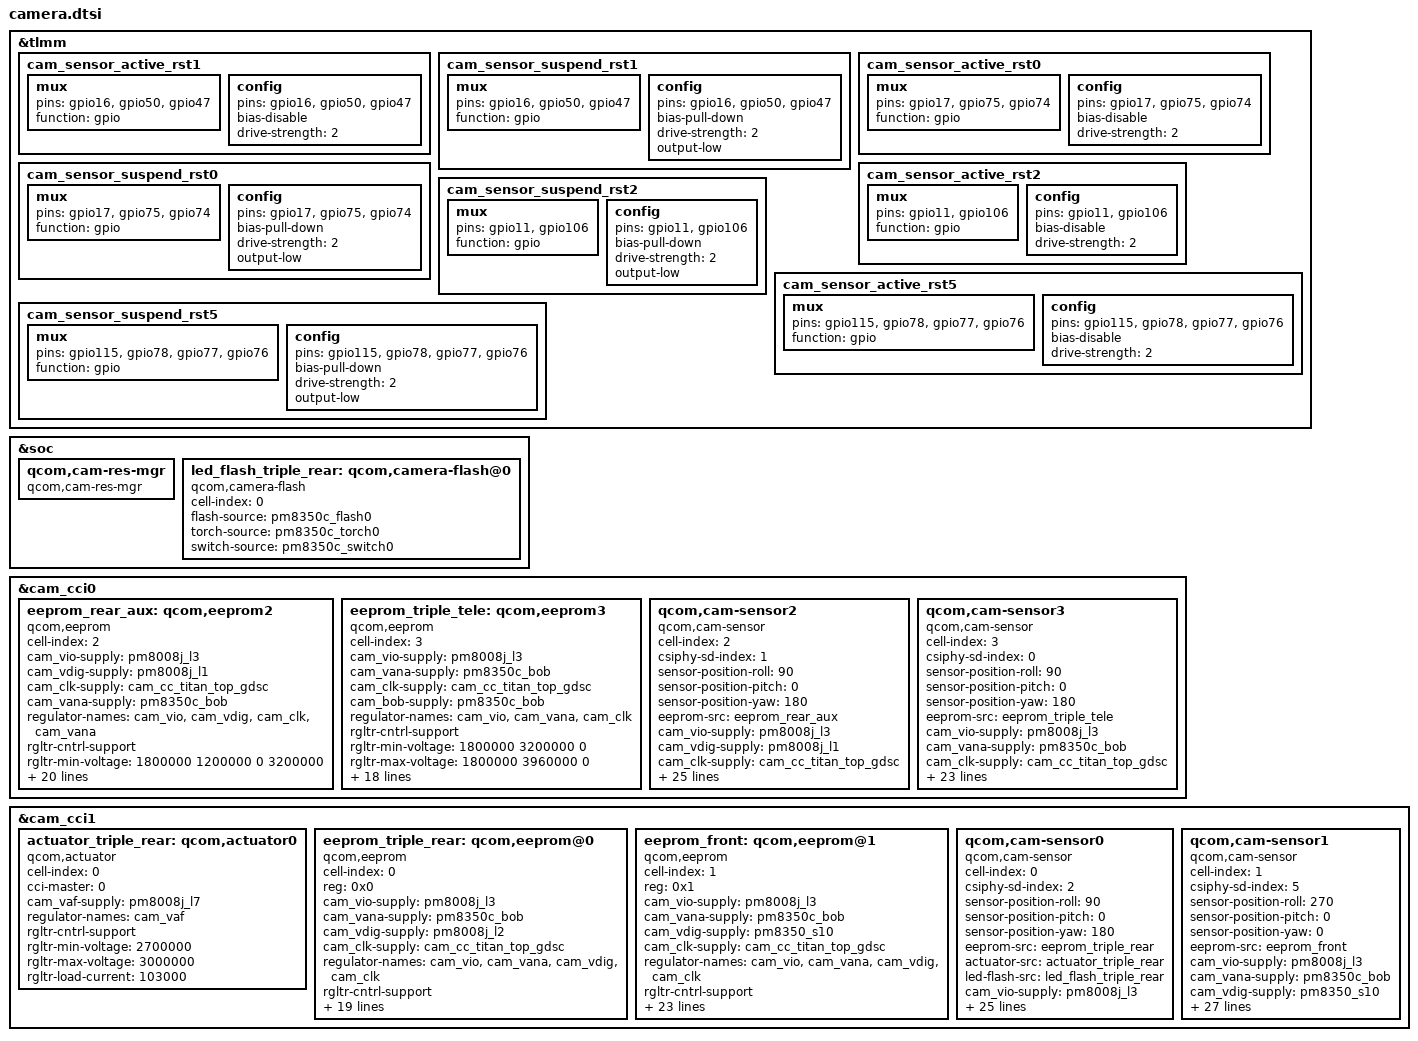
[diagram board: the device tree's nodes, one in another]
#include <dt-bindings/clock/qcom,camcc-lahaina.h>

&tlmm {
	/delete-node/ cam_sensor_active_rst0;
	/delete-node/ cam_sensor_suspend_rst0;
	/delete-node/ cam_sensor_active_rst5;
	/delete-node/ cam_sensor_suspend_rst5;
	/delete-node/ cam_sensor_active_rst1;
	/delete-node/ cam_sensor_suspend_rst1;
	/delete-node/ cam_sensor_active_rst2;
	/delete-node/ cam_sensor_suspend_rst2;
	
	cam_sensor_active_rst1: cam_sensor_active_rst1 {
			/* RESET 1 */
			mux {
				pins = "gpio16","gpio50","gpio47";
				function = "gpio";
			};

			config {
				pins = "gpio16","gpio50","gpio47";
				bias-disable; /* No PULL */
				drive-strength = <2>; /* 2 MA */
			};
		};

		cam_sensor_suspend_rst1: cam_sensor_suspend_rst1 {
			/* RESET 1 */
			mux {
				pins = "gpio16","gpio50","gpio47";
				function = "gpio";
			};

			config {
				pins = "gpio16","gpio50","gpio47";
				bias-pull-down; /* PULL DOWN */
				drive-strength = <2>; /* 2 MA */
				output-low;
			};
		};
	cam_sensor_active_rst0: cam_sensor_active_rst0 {
            /* RESET REAR */
            mux {
                    pins = "gpio17","gpio75","gpio74";
                    function = "gpio";
            };

            config {
                    pins = "gpio17","gpio75","gpio74";
                    bias-disable; /* No PULL */
                    drive-strength = <2>; /* 2 MA */
            };
    };

    cam_sensor_suspend_rst0: cam_sensor_suspend_rst0 {
            /* RESET REAR */
            mux {
                    pins = "gpio17","gpio75","gpio74";
                    function = "gpio";
            };

            config {
                    pins = "gpio17","gpio75","gpio74";
                    bias-pull-down; /* PULL DOWN */
                    drive-strength = <2>; /* 2 MA */
                    output-low;
            };
    };
    cam_sensor_active_rst2: cam_sensor_active_rst2 {
		/* RESET BACK CAM0 */
		mux {
			pins = "gpio11", "gpio106";
			function = "gpio";
		};

		config {
			pins = "gpio11", "gpio106";
			bias-disable; /* No PULL */
			drive-strength = <2>; /* 2 MA */
		};
	};

	cam_sensor_suspend_rst2: cam_sensor_suspend_rst2 {
		/* RESET BACK CAM0 */
		mux {
			pins = "gpio11", "gpio106";
			function = "gpio";
		};

		config {
			pins = "gpio11", "gpio106";
			bias-pull-down; /* PULL DOWN */
			drive-strength = <2>; /* 2 MA */
			output-low;
		};
	};
	cam_sensor_active_rst5: cam_sensor_active_rst5 {
		/* RESET FRONT */
		mux {
			pins = "gpio115", "gpio78", "gpio77", "gpio76";
			function = "gpio";
		};

		config {
			pins = "gpio115", "gpio78", "gpio77", "gpio76";
			bias-disable; /* No PULL */
			drive-strength = <2>; /* 2 MA */
		};
	};

	cam_sensor_suspend_rst5: cam_sensor_suspend_rst5 {
		/* RESET FRONT */
		mux {
			pins = "gpio115", "gpio78", "gpio77", "gpio76";
			function = "gpio";
		};

		config {
			pins = "gpio115", "gpio78", "gpio77", "gpio76";
			bias-pull-down; /* PULL DOWN */
			drive-strength = <2>; /* 2 MA */
			output-low;
		};
	};
};

&soc {
	qcom,cam-res-mgr {
		compatible = "qcom,cam-res-mgr";
		status = "ok";
	};
	led_flash_triple_rear: qcom,camera-flash@0 {
		cell-index = <0>;
		compatible = "qcom,camera-flash";
		flash-source = <&pm8350c_flash0>;
		torch-source = <&pm8350c_torch0>;
		switch-source = <&pm8350c_switch0>;
		status = "ok";
	};
};

&cam_cci0 {
	eeprom_rear_aux: qcom,eeprom2 {
		cell-index = <2>;
		compatible = "qcom,eeprom";
		cam_vio-supply = <&pm8008j_l3>;
		cam_vdig-supply = <&pm8008j_l1>;
		cam_clk-supply = <&cam_cc_titan_top_gdsc>;
		cam_vana-supply = <&pm8350c_bob>;
		regulator-names = "cam_vio","cam_vdig","cam_clk", "cam_vana";
		rgltr-cntrl-support;
		rgltr-min-voltage = <1800000 1200000 0 3200000>;
		rgltr-max-voltage = <1800000 1200000 0 3960000>;
		rgltr-load-current = <5000   74000   0 2000000>;
		gpio-no-mux = <0>;
		pinctrl-names = "cam_default", "cam_suspend";
		pinctrl-0 = <&cam_sensor_mclk1_active
					 &cam_sensor_active_rst1>;
		pinctrl-1 = <&cam_sensor_mclk1_suspend
					 &cam_sensor_suspend_rst1>;
		gpios = <&tlmm 101 0>,
			<&tlmm 16 0>,
			<&tlmm 50 0>,
			<&tlmm 47 0>;
		gpio-reset = <1>;
		gpio-standby = <2>;
		gpio-vana = <3>;
		gpio-req-tbl-num = <0 1 2 3>;
		gpio-req-tbl-flags = <1 0 0 0>;
		gpio-req-tbl-label = "CAMIF_MCLK1",
							 "CAM_RESET1",
							 "CAM_STANDBY1",
							 "CAM_VANA1";
		cci-master = <1>;
		cci-device = <1>;
		status = "ok";
		clocks = <&clock_camcc CAM_CC_MCLK1_CLK>;
		clock-names = "cam_clk";
		clock-cntl-level = "turbo";
		clock-rates = <19200000>;
	};
	//2M-EEPROM
	eeprom_triple_tele: qcom,eeprom3 {
		cell-index = <3>;
		compatible = "qcom,eeprom";
		cam_vio-supply = <&pm8008j_l3>;
		cam_vana-supply = <&pm8350c_bob>;
		//cam_vdig-supply = <&pm8008i_l2>;
		cam_clk-supply = <&cam_cc_titan_top_gdsc>;
		cam_bob-supply = <&pm8350c_bob>;
		regulator-names = "cam_vio", "cam_vana",
			"cam_clk";
		rgltr-cntrl-support;
		rgltr-min-voltage = <1800000 3200000  0>;
		rgltr-max-voltage = <1800000 3960000  0>;
		rgltr-load-current = <10000 2000000  0>;
		gpio-no-mux = <0>;
		pinctrl-names = "cam_default", "cam_suspend";
		pinctrl-0 = <&cam_sensor_mclk0_active
				&cam_sensor_active_rst0>;
		pinctrl-1 = <&cam_sensor_mclk0_suspend
				&cam_sensor_suspend_rst0>;
		gpios = <&tlmm 100 0>,
			<&tlmm 17 0>,
			<&tlmm 75 0>,
			<&tlmm 74 0>;
		gpio-reset = <1>;
		gpio-standby = <2>;
		gpio-vana = <3>;
		gpio-req-tbl-num = <0 1 2 3>;
		gpio-req-tbl-flags = <1 0 0 0>;
		gpio-req-tbl-label = "CAMIF_MCLK0",
					"CAM_RESET0","CAM_STANDBY0","CAM_VANA0";
		cci-master = <0>;
		status = "ok";
		clocks = <&clock_camcc CAM_CC_MCLK0_CLK>;
		clock-names = "cam_clk";
		clock-cntl-level = "nominal";
		clock-rates = <19200000>;
	};
	//8Mback
	qcom,cam-sensor2 {
		cell-index = <2>;
		compatible = "qcom,cam-sensor";
		csiphy-sd-index = <1>;
		sensor-position-roll = <90>;
		sensor-position-pitch = <0>;
		sensor-position-yaw = <180>;
		eeprom-src = <&eeprom_rear_aux>;
		cam_vio-supply = <&pm8008j_l3>;
		cam_vdig-supply = <&pm8008j_l1>;
		cam_clk-supply = <&cam_cc_titan_top_gdsc>;
		cam_vana-supply = <&pm8350c_bob>;
		regulator-names = "cam_vio","cam_vdig","cam_clk", "cam_vana";
		rgltr-cntrl-support;
		rgltr-min-voltage = <1800000 1200000 0 3200000>;
		rgltr-max-voltage = <1800000 1200000 0 3960000>;
		rgltr-load-current = <5000   74000   0 2000000>;
		gpio-no-mux = <0>;
		pinctrl-names = "cam_default", "cam_suspend";
		pinctrl-0 = <&cam_sensor_mclk1_active
					 &cam_sensor_active_rst1>;
		pinctrl-1 = <&cam_sensor_mclk1_suspend
					 &cam_sensor_suspend_rst1>;
		gpios = <&tlmm 101 0>,
			<&tlmm 16 0>,
			<&tlmm 50 0>,
			<&tlmm 47 0>;
		gpio-reset = <1>;
		gpio-standby = <2>;
		gpio-vana = <3>;
		gpio-req-tbl-num = <0 1 2 3>;
		gpio-req-tbl-flags = <1 0 0 0>;
		gpio-req-tbl-label = "CAMIF_MCLK1",
							 "CAM_RESET1",
							 "CAM_STANDBY1",
							 "CAM_VANA1";
		cci-master = <1>;
		cci-device = <1>;
		status = "ok";
		clocks = <&clock_camcc CAM_CC_MCLK1_CLK>;
		clock-names = "cam_clk";
		clock-cntl-level = "turbo";
		clock-rates = <19200000>;
	};
	//2M
	qcom,cam-sensor3 {   
		cell-index = <3>;
		compatible = "qcom,cam-sensor";
		csiphy-sd-index = <0>;
		sensor-position-roll = <90>;
		sensor-position-pitch = <0>;
		sensor-position-yaw = <180>;
		eeprom-src = <&eeprom_triple_tele>;
		//actuator-src = <&actuator_triple_tele>;
		//led-flash-src = <&led_flash_triple_rear_aux>;
		cam_vio-supply = <&pm8008j_l3>;
		cam_vana-supply = <&pm8350c_bob>;
		//cam_vdig-supply = <&pm8008i_l2>;
		cam_clk-supply = <&cam_cc_titan_top_gdsc>;
		cam_bob-supply = <&pm8350c_bob>;
		regulator-names = "cam_vio", "cam_vana",
			"cam_clk";
		rgltr-cntrl-support;
		rgltr-min-voltage = <1800000 3200000  0>;
		rgltr-max-voltage = <1800000 3960000  0>;
		rgltr-load-current = <10000 2000000  0>;
		gpio-no-mux = <0>;
		pinctrl-names = "cam_default", "cam_suspend";
		pinctrl-0 = <&cam_sensor_mclk0_active
				&cam_sensor_active_rst0>;
		pinctrl-1 = <&cam_sensor_mclk0_suspend
				&cam_sensor_suspend_rst0>;
		gpios = <&tlmm 100 0>,
			<&tlmm 17 0>,
			<&tlmm 75 0>,
			<&tlmm 74 0>;
		gpio-reset = <1>;
		gpio-standby = <2>;
		gpio-vana = <3>;
		gpio-req-tbl-num = <0 1 2 3>;
		gpio-req-tbl-flags = <1 0 0 0>;
		gpio-req-tbl-label = "CAMIF_MCLK0",
					"CAM_RESET0","CAM_STANDBY0","CAM_VANA0";
		cci-master = <0>;
		status = "ok";
		clocks = <&clock_camcc CAM_CC_MCLK0_CLK>;
		clock-names = "cam_clk";
		clock-cntl-level = "nominal";
		clock-rates = <19200000>;
	};
};

&cam_cci1 {
	actuator_triple_rear: qcom,actuator0 {
		cell-index = <0>;
		compatible = "qcom,actuator";
		cci-master = <0>;
		cam_vaf-supply = <&pm8008j_l7>;
		regulator-names = "cam_vaf";
		rgltr-cntrl-support;
		rgltr-min-voltage = <2700000>;
		rgltr-max-voltage = <3000000>;
		rgltr-load-current = <103000>;
	};
	eeprom_triple_rear: qcom,eeprom@0 {
		cell-index = <0>;
		compatible = "qcom,eeprom";
		reg = <0x0>;
        cam_vio-supply = <&pm8008j_l3>;
		cam_vana-supply = <&pm8350c_bob>;
		cam_vdig-supply = <&pm8008j_l2>;
		cam_clk-supply = <&cam_cc_titan_top_gdsc>;
		regulator-names = "cam_vio", "cam_vana", "cam_vdig",
			"cam_clk";
		rgltr-cntrl-support;
		rgltr-min-voltage = <1800000 3200000 1050000 0 >;
		rgltr-max-voltage = <1800000 3960000 1150000 0 >;
		rgltr-load-current = <10000 2000000 140000 0 >;
		gpio-no-mux = <0>;
		pinctrl-names = "cam_default", "cam_suspend";
		pinctrl-0 = <&cam_sensor_mclk2_active
				&cam_sensor_active_rst2>;
		pinctrl-1 = <&cam_sensor_mclk2_suspend
				&cam_sensor_suspend_rst2>;
		gpios = <&tlmm 102 0>,
		    <&tlmm 106 0>,
			<&tlmm 11 0>;
		gpio-reset = <1>;
		gpio-vana = <2>;
		gpio-req-tbl-num = <0 1 2>;
		gpio-req-tbl-flags = <1 0 0>;
		gpio-req-tbl-label = "CAMIF_MCLK0",
					"CAM_RESET0",
					"CAM_VANA0";
		cci-master = <0>;
		status = "ok";
		clocks = <&clock_camcc CAM_CC_MCLK2_CLK>;
		clock-names = "cam_clk";
		clock-cntl-level = "nominal";
		clock-rates = <19200000>;
	};
	eeprom_front: qcom,eeprom@1 {
		cell-index = <1>;
		compatible = "qcom,eeprom";
		reg = <0x1>;
		cam_vio-supply = <&pm8008j_l3>;
		cam_vana-supply = <&pm8350c_bob>;
		cam_vdig-supply = <&pm8350_s10>;
		cam_clk-supply = <&cam_cc_titan_top_gdsc>;
		regulator-names = "cam_vio", "cam_vana", "cam_vdig",
			"cam_clk";
		rgltr-cntrl-support;
		rgltr-min-voltage = <1800000 3200000 1800000 0>;
		rgltr-max-voltage = <1800000 3960000 1800000 0>;
		rgltr-load-current = <5000 2000000 5000 0>;
		gpio-no-mux = <0>;
		pinctrl-names = "cam_default", "cam_suspend";
		pinctrl-0 = <&cam_sensor_mclk5_active
				 &cam_sensor_active_rst5>;
		pinctrl-1 = <&cam_sensor_mclk5_suspend
				 &cam_sensor_suspend_rst5>;
		gpios = <&tlmm 105 0>,
			<&tlmm 115 0>,
			<&tlmm 78 0>,
			<&tlmm 77 0>,
			<&tlmm 76 0>;
		gpio-reset = <1>;
		gpio-vdig = <2>;
		gpio-vana = <3>;
		gpio-standby = <4>;
		gpio-req-tbl-num = <0 1 2 3 4>;
		gpio-req-tbl-flags = <1 0 0 0 0>;
		gpio-req-tbl-label = "CAMIF_MCLK5",
					"CAM_RESET5",
					"CAM_VDIG5",
					"CAM_VANA5",
					"CAM_STANDBY5";
		cci-master = <1>;
		cci-device = <1>;
		status = "ok";
		clocks = <&clock_camcc CAM_CC_MCLK5_CLK>;
		clock-names = "cam_clk";
		clock-cntl-level = "nominal";
		clock-rates = <19200000>;
	};
	qcom,cam-sensor0 {
		cell-index = <0>;
		compatible = "qcom,cam-sensor";
		csiphy-sd-index = <2>;
		sensor-position-roll = <90>;
		sensor-position-pitch = <0>;
		sensor-position-yaw = <180>;
		eeprom-src = <&eeprom_triple_rear>;
		actuator-src = <&actuator_triple_rear>;
		led-flash-src = <&led_flash_triple_rear>;
		cam_vio-supply = <&pm8008j_l3>;
		cam_vana-supply = <&pm8350c_bob>;
		cam_vdig-supply = <&pm8008j_l2>;
		cam_clk-supply = <&cam_cc_titan_top_gdsc>;
		regulator-names = "cam_vio", "cam_vana", "cam_vdig",
			"cam_clk";
		rgltr-cntrl-support;
		rgltr-min-voltage = <1800000 3200000 1050000 0 >;
		rgltr-max-voltage = <1800000 3960000 1150000 0 >;
		rgltr-load-current = <10000 2000000 140000 0 >;
		gpio-no-mux = <0>;
		pinctrl-names = "cam_default", "cam_suspend";
		pinctrl-0 = <&cam_sensor_mclk2_active
				&cam_sensor_active_rst2>;
		pinctrl-1 = <&cam_sensor_mclk2_suspend
				&cam_sensor_suspend_rst2>;
		gpios = <&tlmm 102 0>,
		    <&tlmm 106 0>,
			<&tlmm 93 0>;
		gpio-reset = <1>;
		gpio-vana = <2>;
		gpio-req-tbl-num = <0 1 2>;
		gpio-req-tbl-flags = <1 0 0>;
		gpio-req-tbl-label = "CAMIF_MCLK0",
					"CAM_RESET0",
					"CAM_VANA0";
		cci-master = <0>;
		status = "ok";
		clocks = <&clock_camcc CAM_CC_MCLK2_CLK>;
		clock-names = "cam_clk";
		clock-cntl-level = "nominal";
		clock-rates = <19200000>;
	};
	qcom,cam-sensor1 {
		cell-index = <1>;
		compatible = "qcom,cam-sensor";
		csiphy-sd-index = <5>;
		sensor-position-roll = <270>;
		sensor-position-pitch = <0>;
		sensor-position-yaw = <0>;
		eeprom-src = <&eeprom_front>;
		cam_vio-supply = <&pm8008j_l3>;
		cam_vana-supply = <&pm8350c_bob>;
		cam_vdig-supply = <&pm8350_s10>;
		cam_clk-supply = <&cam_cc_titan_top_gdsc>;
		regulator-names = "cam_vio", "cam_vana", "cam_vdig",
			"cam_clk";
		rgltr-cntrl-support;
		rgltr-min-voltage = <1800000 3200000 1800000 0>;
		rgltr-max-voltage = <1800000 3960000 1800000 0>;
		rgltr-load-current = <5000 2000000 5000 0>;
		gpio-no-mux = <0>;
		pinctrl-names = "cam_default", "cam_suspend";
		pinctrl-0 = <&cam_sensor_mclk5_active
				 &cam_sensor_active_rst5>;
		pinctrl-1 = <&cam_sensor_mclk5_suspend
				 &cam_sensor_suspend_rst5>;
		gpios = <&tlmm 105 0>,
			<&tlmm 115 0>,
			<&tlmm 78 0>,
			<&tlmm 77 0>,
			<&tlmm 76 0>;
		gpio-reset = <1>;
		gpio-vdig = <2>;
		gpio-vana = <3>;
		gpio-standby = <4>;
		gpio-req-tbl-num = <0 1 2 3 4>;
		gpio-req-tbl-flags = <1 0 0 0 0>;
		gpio-req-tbl-label = "CAMIF_MCLK5",
					"CAM_RESET5",
					"CAM_VDIG5",
					"CAM_VANA5",
					"CAM_STANDBY5";
		cci-master = <1>;
		cci-device = <1>;
		status = "ok";
		clocks = <&clock_camcc CAM_CC_MCLK5_CLK>;
		clock-names = "cam_clk";
		clock-cntl-level = "nominal";
		clock-rates = <19200000>;
	};
};
